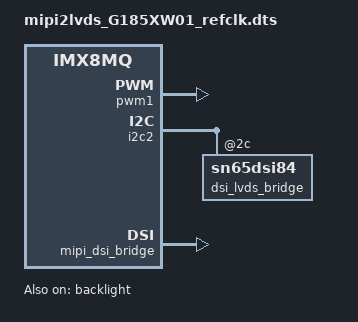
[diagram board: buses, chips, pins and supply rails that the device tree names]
/dts-v1/;
/plugin/;
/ {
	compatible = "fsl,imx8mq";

	fragment@0 {
		target = <&pwm1>;
		__overlay__ {
			status = "okay";
		};
	};
	fragment@1 {
		target = <&backlight>;
		__overlay__ {
			status = "okay";
			pwms = <&pwm1 0 4000000 0>;
                        minimal-brightness-level = <26>;
		};
	};
	fragment@2 {
		target = <&i2c2>;
		__overlay__ {
			status = "okay";
			dsi_lvds_bridge: sn65dsi84@2c {
				status = "okay";
				lvds-clk-rate = <72000000>;
				lvds-format = <2>;
				lvds-bpp = <24>;
				lvds-width-mm = <409>;
				lvds-height-mm = <230>;
				sync_delay = <32>;
                                refclk_multiplier=<3>;
                                clk_from_refclk;

				t1=<0>;
				t2=<1>;
				t3=<500>;
				t4=<200>;
				t5=<1>;
				t6=<0>;
				t7=<1000>;

				bpc=<8>;
				bus-format = <0x100a>;
				dsi,flags = <0x3>;
				dsi,format = <0>;
				dsi-lanes = <4>;

				display-timings {
					lvds {
						clock-frequency = <72000000>;
						hactive = <1360>;
						vactive = <768>;
						hfront-porch = <50>;
						hback-porch = <50>;
						hsync-len = <19>;
						vfront-porch = <15>;
						vsync-len = <10>;
						vback-porch = <15>;
						hsync-active = <0>;
						vsync-active = <0>;
						de-active = <0>;
						pixelclk-active = <0>;
					};
				};
			};
		};
	};
	fragment@3 {
		target = <&mipi_dsi_bridge>;
		__overlay__ {
			status = "okay";
			panel@0 {
				status = "disabled";
			};
		};
	};
	fragment@4 {
		target = <&mipi_dsi>;
		__overlay__ {
			sync-pol = <1>;
			pwr-delay = <100>;
			//best-match;
		};
	};
	fragment@5 {
		target = <&lcdif>;
		__overlay__ {
			max-res = <4096>, <4096>;
		};
	};

};
